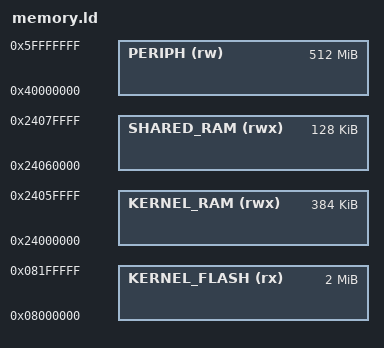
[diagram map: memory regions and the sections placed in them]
/* witte_linum/memory.ld — STM32H753ZI Layer 3 chip input. */
MEMORY {
	KERNEL_FLASH  (rx)  : ORIGIN = 0x08000000, LENGTH = 2048K
	KERNEL_RAM    (rwx) : ORIGIN = 0x24000000, LENGTH = 384K
	SHARED_RAM    (rwx) : ORIGIN = 0x24060000, LENGTH = 128K
	PERIPH        (rw)  : ORIGIN = 0x40000000, LENGTH = 512M
}

ULMK_KERNEL_STACK_SIZE = 0x1000;
ULMK_ISR_STACK_SIZE    = 0x0800;
ULMK_MPU_ALIGN         = 32;

HAVE_CSA        = 0;
HAVE_SMALL_DATA = 0;
HAVE_BMHD       = 0;
